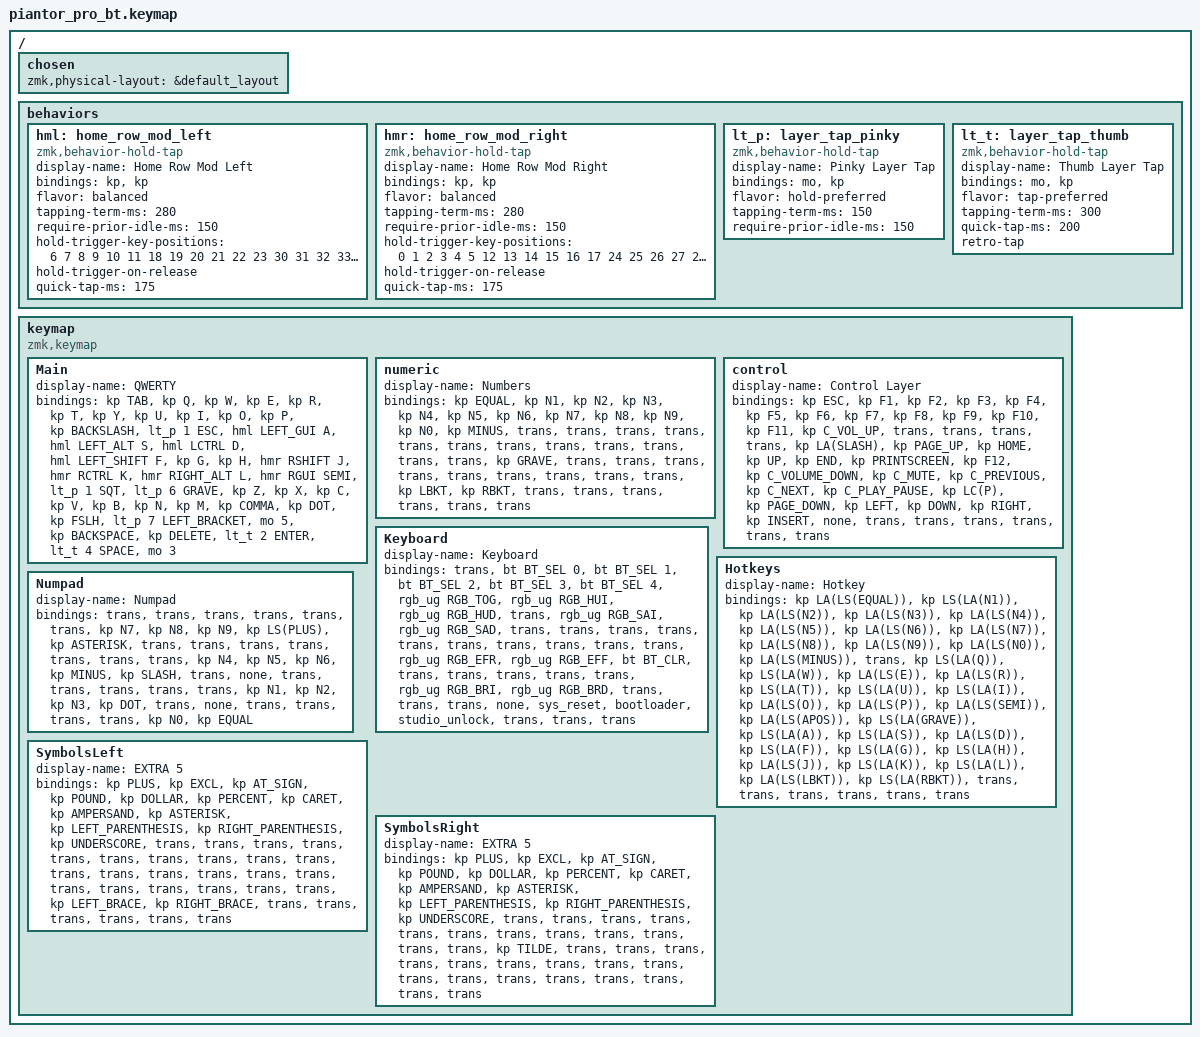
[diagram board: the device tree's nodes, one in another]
/*
 * Copyright (c) 2020 The ZMK Contributors
 *
 * SPDX-License-Identifier: MIT
 */

#include <behaviors.dtsi>
#include <dt-bindings/zmk/bt.h>
#include <dt-bindings/zmk/keys.h>
#include <dt-bindings/zmk/rgb.h>

/ {
    chosen { zmk,physical-layout = &default_layout; };
};

/ {
    behaviors {
        // Plain hold-tap for the outer/thumb keys: no positional filter,
        // since these are not typed in rolls with their own hand.
        // Home row mods, left hand: only resolves to a modifier when the
        // next key pressed is on the right half or a thumb.

        hml: home_row_mod_left {
            compatible = "zmk,behavior-hold-tap";
            display-name = "Home Row Mod Left";
            bindings = <&kp>, <&kp>;

            #binding-cells = <2>;
            flavor = "balanced";
            tapping-term-ms = <280>;

            // No quick-tap: it would force a tap when the same key was
            // tapped moments ago, leaking an "f" in sequences like "if I".

            require-prior-idle-ms = <150>;
            hold-trigger-key-positions = <6 7 8 9 10 11 18 19 20 21 22 23 30 31 32 33 34 35 36 37 38 39 40 41>;
            hold-trigger-on-release;
            quick-tap-ms = <175>;
        };

        // Home row mods, right hand: mirror of the above.

        hmr: home_row_mod_right {
            compatible = "zmk,behavior-hold-tap";
            display-name = "Home Row Mod Right";
            bindings = <&kp>, <&kp>;

            #binding-cells = <2>;
            flavor = "balanced";
            tapping-term-ms = <280>;

            // No quick-tap: it would force a tap when the same key was
            // tapped moments ago, leaking an "f" in sequences like "if I".

            require-prior-idle-ms = <150>;
            hold-trigger-key-positions = <0 1 2 3 4 5 12 13 14 15 16 17 24 25 26 27 28 29 36 37 38 39 40 41>;
            hold-trigger-on-release;
            quick-tap-ms = <175>;
        };

        // Pinky layer-taps (Esc, ', `, [). hold-preferred on purpose: these
        // are chorded, so the layer must engage the moment the second key
        // goes down rather than after a tapping term. No positional filter,
        // since same-hand keys (Esc + 2/3/4) are used, so require-prior-idle
        // is the only thing stopping hold-preferred from firing the layer on
        // the next letter while typing -- without it "don't" becomes "don5"
        // (' is pos 23, layer 1; t is pos 5, which on layer 1 is N5).
        //
        // Known trade-off: the guard decides at key-down, so one of these
        // pressed within 150ms of a keystroke is forced to a tap however long
        // it is then held. Measured median gap between keystrokes is 122ms,
        // so that fires fairly often mid-typing. Left as-is deliberately --
        // a chord failing here looked identical to the contact chatter on
        // position 35, so tune this only against a known-good switch.

        lt_p: layer_tap_pinky {
            compatible = "zmk,behavior-hold-tap";
            display-name = "Pinky Layer Tap";
            bindings = <&mo>, <&kp>;

            #binding-cells = <2>;
            flavor = "hold-preferred";
            tapping-term-ms = <150>;
            require-prior-idle-ms = <150>;
        };

        // Thumb layer-taps (Enter, Space). These are typing keys first and
        // layer keys second, so the tap has to be the reliable action: stock
        // &lt is tap-preferred with a 200ms term, short enough that a thumb
        // lingering mid-sentence became a layer hold and the keycode was
        // never sent. A 300ms term plus retro-tap fixes that -- retro-tap
        // emits the tap on release when the key was held with no other key
        // pressed, so even a slow deliberate Enter still types.
        //
        // Deliberately no require-prior-idle-ms. That guard forces a tap
        // whenever a key was pressed in the preceding window, however long
        // the thumb is then held, which would make layers 2 and 4 unreachable
        // until typing pauses -- unacceptable for a nav layer used mid-edit.
        // It belongs on the home row mods (which have it) where a misfire
        // costs a wrong modifier, not on layer-taps.

        lt_t: layer_tap_thumb {
            compatible = "zmk,behavior-hold-tap";
            display-name = "Thumb Layer Tap";
            bindings = <&mo>, <&kp>;

            #binding-cells = <2>;
            flavor = "tap-preferred";
            tapping-term-ms = <300>;
            quick-tap-ms = <200>;
            retro-tap;
        };
    };

    keymap {
        compatible = "zmk,keymap";

        Main {
            display-name = "QWERTY";

            // --------------------------------------------------------------------------------
            // |  TAB |  Q  |  W  |  E  |  R  |  T  |  Y  |  U   |  I  |  O  |  P  | BSPC |
            // | CTRL |  A  |  S  |  D  |  F  |  G  |  H  |  J   |  K  |  L  |  ;  |  '   |
            // | SHFT |  Z  |  X  |  C  |  V  |  B  |  N  |  M   |  ,  |  .  |  /  | ESC  |
            //                    | GUI | LWR | SPC | ENT | RSE  | ALT |

            bindings = <
&kp TAB  &kp Q  &kp W  &kp E  &kp R  &kp T  &kp Y  &kp U  &kp I  &kp O  &kp P  &kp BACKSLASH  &lt_p 1 ESC  &hml LEFT_GUI A  &hml LEFT_ALT S  &hml LCTRL D  &hml LEFT_SHIFT F  &kp G  &kp H  &hmr RSHIFT J  &hmr RCTRL K  &hmr RIGHT_ALT L  &hmr RGUI SEMI  &lt_p 1 SQT  &lt_p 6 GRAVE  &kp Z  &kp X  &kp C  &kp V  &kp B  &kp N  &kp M  &kp COMMA  &kp DOT  &kp FSLH  &lt_p 7 LEFT_BRACKET  &mo 5  &kp BACKSPACE  &kp DELETE  &lt_t 2 ENTER  &lt_t 4 SPACE  &mo 3
            >;
        };

        numeric {
            display-name = "Numbers";
            bindings = <
&kp EQUAL  &kp N1  &kp N2  &kp N3  &kp N4  &kp N5  &kp N6  &kp N7  &kp N8  &kp N9  &kp N0  &kp MINUS  &trans  &trans  &trans  &trans  &trans  &trans  &trans  &trans  &trans  &trans  &trans  &trans  &kp GRAVE  &trans  &trans  &trans  &trans  &trans  &trans  &trans  &trans  &trans  &kp LBKT  &kp RBKT  &trans  &trans  &trans  &trans  &trans  &trans
            >;
        };

        control {
            display-name = "Control Layer";
            bindings = <
&kp ESC  &kp F1  &kp F2  &kp F3  &kp F4  &kp F5  &kp F6  &kp F7  &kp F8  &kp F9  &kp F10  &kp F11  &kp C_VOL_UP  &trans  &trans  &trans  &trans  &kp LA(SLASH)  &kp PAGE_UP  &kp HOME  &kp UP  &kp END  &kp PRINTSCREEN  &kp F12  &kp C_VOLUME_DOWN  &kp C_MUTE  &kp C_PREVIOUS  &kp C_NEXT  &kp C_PLAY_PAUSE  &kp LC(P)  &kp PAGE_DOWN  &kp LEFT  &kp DOWN  &kp RIGHT  &kp INSERT  &none  &trans  &trans  &trans  &trans  &trans  &trans
            >;
        };

        Keyboard {
            display-name = "Keyboard";

            // -----------------------------------------------------------------------------------------
            // |  TAB |  1  |  2  |  3  |  4  |  5    |  6  |  7  |  8  |  9  |  0  | BSPC |
            // | CTRL | BT1 | BT2 | BT3 | BT4 | BT5   | LFT | DWN |  UP | RGT |     |      |
            // | SHFT | BTCR| RGB | RST | BOOT| Unlock|     |     |     |     |     |      |
            //                    | GUI |     | SPC   | ENT |     | ALT |

            bindings = <
&trans  &bt BT_SEL 0  &bt BT_SEL 1  &bt BT_SEL 2  &bt BT_SEL 3  &bt BT_SEL 4  &rgb_ug RGB_TOG  &rgb_ug RGB_HUI  &rgb_ug RGB_HUD  &trans  &rgb_ug RGB_SAI  &rgb_ug RGB_SAD  &trans  &trans  &trans  &trans  &trans  &trans  &trans  &trans  &trans  &trans  &rgb_ug RGB_EFR  &rgb_ug RGB_EFF  &bt BT_CLR  &trans  &trans  &trans  &trans  &trans  &rgb_ug RGB_BRI  &rgb_ug RGB_BRD  &trans  &trans  &trans  &none  &sys_reset  &bootloader  &studio_unlock  &trans  &trans  &trans
            >;
        };

        Hotkeys {
            display-name = "Hotkey";
            bindings = <
&kp LA(LS(EQUAL))  &kp LS(LA(N1))  &kp LA(LS(N2))  &kp LA(LS(N3))  &kp LA(LS(N4))  &kp LA(LS(N5))  &kp LA(LS(N6))  &kp LA(LS(N7))  &kp LA(LS(N8))  &kp LA(LS(N9))  &kp LA(LS(N0))  &kp LA(LS(MINUS))  &trans  &kp LS(LA(Q))  &kp LS(LA(W))  &kp LA(LS(E))  &kp LA(LS(R))  &kp LS(LA(T))  &kp LS(LA(U))  &kp LS(LA(I))  &kp LA(LS(O))  &kp LA(LS(P))  &kp LA(LS(SEMI))  &kp LA(LS(APOS))  &kp LS(LA(GRAVE))  &kp LS(LA(A))  &kp LS(LA(S))  &kp LA(LS(D))  &kp LS(LA(F))  &kp LS(LA(G))  &kp LS(LA(H))  &kp LA(LS(J))  &kp LS(LA(K))  &kp LS(LA(L))  &kp LA(LS(LBKT))  &kp LS(LA(RBKT))  &trans  &trans  &trans  &trans  &trans  &trans
            >;
        };

        Numpad {
            display-name = "Numpad";
            bindings = <
&trans  &trans  &trans  &trans  &trans  &trans  &kp N7  &kp N8  &kp N9  &kp LS(PLUS)  &kp ASTERISK  &trans  &trans  &trans  &trans  &trans  &trans  &trans  &kp N4  &kp N5  &kp N6  &kp MINUS  &kp SLASH  &trans  &none  &trans  &trans  &trans  &trans  &trans  &kp N1  &kp N2  &kp N3  &kp DOT  &trans  &none  &trans  &trans  &trans  &trans  &kp N0  &kp EQUAL
            >;
        };

        SymbolsLeft {
            display-name = "EXTRA 5";
            bindings = <
&kp PLUS  &kp EXCL  &kp AT_SIGN  &kp POUND  &kp DOLLAR  &kp PERCENT  &kp CARET  &kp AMPERSAND  &kp ASTERISK  &kp LEFT_PARENTHESIS  &kp RIGHT_PARENTHESIS  &kp UNDERSCORE  &trans  &trans  &trans  &trans  &trans  &trans  &trans  &trans  &trans  &trans  &trans  &trans  &trans  &trans  &trans  &trans  &trans  &trans  &trans  &trans  &trans  &trans  &kp LEFT_BRACE  &kp RIGHT_BRACE  &trans  &trans  &trans  &trans  &trans  &trans
            >;
        };

        SymbolsRight {
            display-name = "EXTRA 5";
            bindings = <
&kp PLUS  &kp EXCL  &kp AT_SIGN  &kp POUND  &kp DOLLAR  &kp PERCENT  &kp CARET  &kp AMPERSAND  &kp ASTERISK  &kp LEFT_PARENTHESIS  &kp RIGHT_PARENTHESIS  &kp UNDERSCORE  &trans  &trans  &trans  &trans  &trans  &trans  &trans  &trans  &trans  &trans  &trans  &trans  &kp TILDE  &trans  &trans  &trans  &trans  &trans  &trans  &trans  &trans  &trans  &trans  &trans  &trans  &trans  &trans  &trans  &trans  &trans
            >;
        };
    };
};
